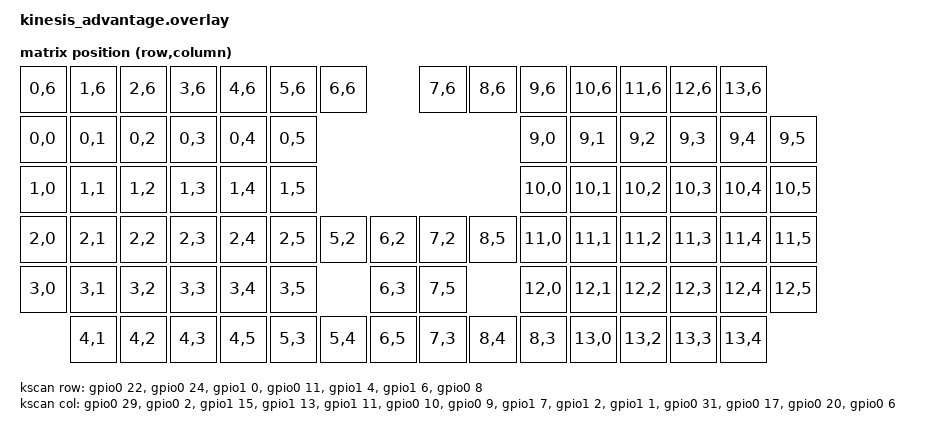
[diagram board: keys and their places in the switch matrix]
// This file was generated from a template. Edit it to match your keyboard.
// See https://zmk.dev/docs/development/hardware-integration/new-shield for more
// instructions.

#include <dt-bindings/zmk/matrix_transform.h>

#include "kinesis_advantage-layouts.dtsi"

/ {
    chosen {
        zmk,physical-layout = &default_layout;
    };

    kscan: kscan {
        // If the hardware does not use a switch matrix, change this to the
        // appropriate driver and update the properties below to match.
        // See https://zmk.dev/docs/config/kscan for supported key scan drivers.
        compatible = "zmk,kscan-gpio-matrix";
        // Set this to "col2row" or "row2col" to match the hardware. If using
        // "row2col", change the col-gpios to (GPIO_ACTIVE_HIGH | GPIO_PULL_DOWN)
        // and the row-gpios to GPIO_ACTIVE_HIGH.
        diode-direction = "row2col";
        wakeup-source;

        // Replace these comments with the GPIO pins in the matrix.
        // See https://zmk.dev/docs/development/hardware-integration/new-shield#shield-overlays
        // row-gpios
        //     = <&gpio0 29 (GPIO_ACTIVE_HIGH)>  // R0
        //     , <&gpio0 2 (GPIO_ACTIVE_HIGH)>   // R1
        //     , <&gpio1 15 (GPIO_ACTIVE_HIGH)>  // R2
        //     , <&gpio1 13 (GPIO_ACTIVE_HIGH)>  // R3
        //     , <&gpio1 11 (GPIO_ACTIVE_HIGH)>  // R4
        //     , <&gpio0 10 (GPIO_ACTIVE_HIGH)>  // R5
        //     , <&gpio0 9 (GPIO_ACTIVE_HIGH)>   // R6
        //     , <&gpio1 7 (GPIO_ACTIVE_HIGH)>   // R7
        //     , <&gpio1 2 (GPIO_ACTIVE_HIGH)>   // R8
        //     , <&gpio1 1 (GPIO_ACTIVE_HIGH)>   // R9
        //     , <&gpio0 31 (GPIO_ACTIVE_HIGH)>  // R10
        //     , <&gpio0 17 (GPIO_ACTIVE_HIGH)>  // R11
        //     , <&gpio0 20 (GPIO_ACTIVE_HIGH)>  // R12
        //     , <&gpio0 6 (GPIO_ACTIVE_HIGH)>   // R13
        //     ;

        // col-gpios
        //     = <&gpio0 22 (GPIO_ACTIVE_HIGH | GPIO_PULL_DOWN)>  // C0
        //     , <&gpio0 24 (GPIO_ACTIVE_HIGH | GPIO_PULL_DOWN)>  // C1
        //     , <&gpio1 0 (GPIO_ACTIVE_HIGH | GPIO_PULL_DOWN)>   // C2
        //     , <&gpio0 11 (GPIO_ACTIVE_HIGH | GPIO_PULL_DOWN)>  // C3
        //     , <&gpio1 4 (GPIO_ACTIVE_HIGH | GPIO_PULL_DOWN)>   // C4
        //     , <&gpio1 6 (GPIO_ACTIVE_HIGH | GPIO_PULL_DOWN)>   // C5
        //     , <&gpio0 8 (GPIO_ACTIVE_HIGH | GPIO_PULL_DOWN)>   // C6
        //     ;
        col-gpios
            = <&gpio0 29 (GPIO_ACTIVE_HIGH)>  // R0
            , <&gpio0 2 (GPIO_ACTIVE_HIGH)>   // R1
            , <&gpio1 15 (GPIO_ACTIVE_HIGH)>  // R2
            , <&gpio1 13 (GPIO_ACTIVE_HIGH)>  // R3
            , <&gpio1 11 (GPIO_ACTIVE_HIGH)>  // R4
            , <&gpio0 10 (GPIO_ACTIVE_HIGH)>  // R5
            , <&gpio0 9 (GPIO_ACTIVE_HIGH)>   // R6
            , <&gpio1 7 (GPIO_ACTIVE_HIGH)>   // R7
            , <&gpio1 2 (GPIO_ACTIVE_HIGH)>   // R8
            , <&gpio1 1 (GPIO_ACTIVE_HIGH)>   // R9
            , <&gpio0 31 (GPIO_ACTIVE_HIGH)>  // R10
            , <&gpio0 17 (GPIO_ACTIVE_HIGH)>  // R11
            , <&gpio0 20 (GPIO_ACTIVE_HIGH)>  // R12
            , <&gpio0 6 (GPIO_ACTIVE_HIGH)>   // R13
            ;

        row-gpios
            = <&gpio0 22 (GPIO_ACTIVE_HIGH | GPIO_PULL_DOWN)>  // C0
            , <&gpio0 24 (GPIO_ACTIVE_HIGH | GPIO_PULL_DOWN)>  // C1
            , <&gpio1 0 (GPIO_ACTIVE_HIGH | GPIO_PULL_DOWN)>   // C2
            , <&gpio0 11 (GPIO_ACTIVE_HIGH | GPIO_PULL_DOWN)>  // C3
            , <&gpio1 4 (GPIO_ACTIVE_HIGH | GPIO_PULL_DOWN)>   // C4
            , <&gpio1 6 (GPIO_ACTIVE_HIGH | GPIO_PULL_DOWN)>   // C5
            , <&gpio0 8 (GPIO_ACTIVE_HIGH | GPIO_PULL_DOWN)>   // C6
            ;
    };

    default_transform: default_transform {
        // See https://zmk.dev/docs/development/hardware-integration/new-shield#matrix-transform
        // for how to configure this
        compatible = "zmk,matrix-transform";
        // columns = <7>;
        // rows = <14>;
        columns = <14>;
        rows = <7>;

        map = <
            RC(0,6) RC(1,6) RC(2,6) RC(3,6) RC(4,6) RC(5,6) RC(6,6) RC(7,6) RC(8,6)                            RC(9,6)  RC(10,6) RC(11,6) RC(12,6) RC(13,6)
            RC(0,0) RC(0,1) RC(0,2) RC(0,3) RC(0,4) RC(0,5)                                                    RC(9,0)  RC(9,1)  RC(9,2)  RC(9,3)  RC(9,4)  RC(9,5)
            RC(1,0) RC(1,1) RC(1,2) RC(1,3) RC(1,4) RC(1,5)                                                    RC(10,0) RC(10,1) RC(10,2) RC(10,3) RC(10,4) RC(10,5)
            RC(2,0) RC(2,1) RC(2,2) RC(2,3) RC(2,4) RC(2,5)         RC(5,2) RC(6,2) RC(7,2) RC(8,5)            RC(11,0) RC(11,1) RC(11,2) RC(11,3) RC(11,4) RC(11,5)
            RC(3,0) RC(3,1) RC(3,2) RC(3,3) RC(3,4) RC(3,5)                 RC(6,3) RC(7,5)                    RC(12,0) RC(12,1) RC(12,2) RC(12,3) RC(12,4) RC(12,5)
                    RC(4,1) RC(4,2) RC(4,3) RC(4,5)         RC(5,3) RC(5,4) RC(6,5) RC(7,3) RC(8,4) RC(8,3)             RC(13,0) RC(13,2) RC(13,3) RC(13,4)
        >;
    };
};
